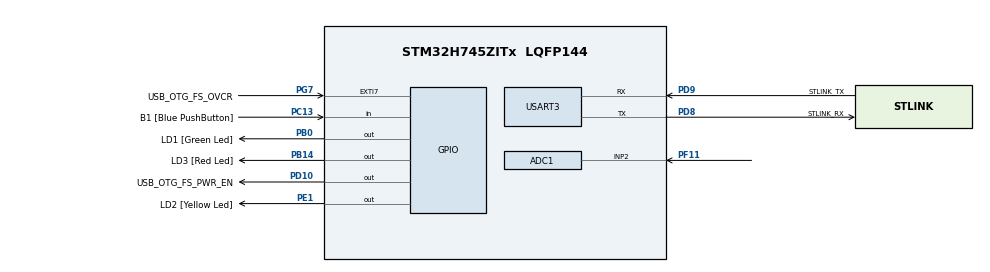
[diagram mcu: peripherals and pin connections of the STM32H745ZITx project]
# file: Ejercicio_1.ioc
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ADC1.Channel-0\#ChannelRegularConversion=ADC_CHANNEL_2
ADC1.ContinuousConvMode=ENABLE
ADC1.NbrOfConversionFlag=1
ADC1.OffsetNumber-0\#ChannelRegularConversion=ADC_OFFSET_NONE
ADC1.OffsetSignedSaturation-0\#ChannelRegularConversion=DISABLE
ADC1.Rank-0\#ChannelRegularConversion=1
ADC1.Resolution=ADC_RESOLUTION_8B
ADC1.SamplingTime-0\#ChannelRegularConversion=ADC_SAMPLETIME_1CYCLE_5
ADC1.master=1
CortexM4.IPs=FATFS_M4\:I,FREERTOS_M4\:I,IWDG2\:I,RCC,WWDG2\:I,DMA,BDMA,MDMA,NVIC2\:I,USART3,DEBUG,USB_DEVICE_M4\:I,USB_HOST_M4\:I,PDM2PCM_M4\:I,PWR,RESMGR_UTILITY,SYS_M4\:I,CORTEX_M4\:I,OPENAMP_M4\:I,VREFBUF,GPIO
CortexM7.IPs=FATFS_M7\:I,FREERTOS_M7\:I,IWDG1\:I,RCC\:I,WWDG1\:I,DMA\:I,BDMA\:I,MDMA\:I,NVIC1\:I,SYS\:I,USART3\:I,CORTEX_M7\:I,DEBUG\:I,USB_DEVICE_M7\:I,USB_HOST_M7\:I,PDM2PCM_M7\:I,PWR\:I,RESMGR_UTILITY\:I,OPENAMP_M7\:I,VREFBUF\:I,GPIO\:I,ADC1\:I
Mcu.Family=STM32H7
Mcu.Name=STM32H745ZITx
Mcu.Package=LQFP144
NVIC1.PriorityGroup=NVIC_PRIORITYGROUP_4
NVIC2.PriorityGroup=NVIC_PRIORITYGROUP_4
PA1.PinAttribute=CortexM7
PA1.Signal=ETH_REF_CLK
PA11.PinAttribute=CortexM7
PA11.Signal=USB_OTG_FS_DM
PA12.PinAttribute=CortexM7
PA12.Signal=USB_OTG_FS_DP
PA2.PinAttribute=CortexM7
PA2.Signal=ETH_MDIO
PA7.PinAttribute=CortexM7
PA7.Signal=ETH_CRS_DV
PA8.PinAttribute=CortexM7
PA8.Signal=USB_OTG_FS_SOF
PA9.PinAttribute=CortexM7
PA9.Signal=USB_OTG_FS_VBUS
PB0.GPIO_Label=LD1 [Green Led]
PB0.PinAttribute=Free
PB0.Signal=GPIO_Output
PB13.PinAttribute=CortexM7
PB13.Signal=ETH_TXD1
PB14.GPIO_Label=LD3 [Red Led]
PB14.PinAttribute=Free
PB14.Signal=GPIO_Output
PC1.PinAttribute=CortexM7
PC1.Signal=ETH_MDC
PC13.GPIO_Label=B1 [Blue PushButton]
PC13.PinAttribute=Free
PC13.Signal=GPIO_Input
PC14-OSC32_IN\ (OSC32_IN).Mode=LSE-External-Oscillator
PC14-OSC32_IN\ (OSC32_IN).PinAttribute=CortexM7
PC14-OSC32_IN\ (OSC32_IN).Signal=RCC_OSC32_IN
PC15-OSC32_OUT\ (OSC32_OUT).Mode=LSE-External-Oscillator
PC15-OSC32_OUT\ (OSC32_OUT).PinAttribute=CortexM7
PC15-OSC32_OUT\ (OSC32_OUT).Signal=RCC_OSC32_OUT
PC4.PinAttribute=CortexM7
PC4.Signal=ETH_RXD0
PC5.PinAttribute=CortexM7
PC5.Signal=ETH_RXD1
PD10.GPIO_Label=USB_OTG_FS_PWR_EN
PD10.PinAttribute=Free
PD10.Signal=GPIO_Output
PD8.GPIO_Label=STLINK_RX
PD8.Mode=Asynchronous
PD8.PinAttribute=CortexM7
PD8.Signal=USART3_TX
PD9.GPIO_Label=STLINK_TX
PD9.Mode=Asynchronous
PD9.PinAttribute=CortexM7
PD9.Signal=USART3_RX
PE1.GPIO_Label=LD2 [Yellow Led]
PE1.PinAttribute=Free
PE1.Signal=GPIO_Output
PF11.PinAttribute=CortexM7
PF11.Signal=SharedAnalog_PF11
PG11.PinAttribute=CortexM7
PG11.Signal=ETH_TX_EN
PG13.PinAttribute=CortexM7
PG13.Signal=ETH_TXD0
PG7.GPIO_Label=USB_OTG_FS_OVCR
PG7.PinAttribute=Free
PG7.Signal=GPXTI7
PH0-OSC_IN\ (PH0).Mode=HSE-External-Clock-Source
PH0-OSC_IN\ (PH0).PinAttribute=CortexM7
PH0-OSC_IN\ (PH0).Signal=RCC_OSC_IN
PH1-OSC_OUT\ (PH1).PinAttribute=CortexM7
PH1-OSC_OUT\ (PH1).Signal=RCC_OSC_OUT
ProjectManager.HeapSize=M4-0x200,M7-0x200
ProjectManager.StackSize=M4-0x400,M7-0x400
ProjectManager.TargetToolchain=STM32CubeIDE
RCC.ADCFreq_Value=76000000
RCC.APB1Freq_Value=120000000
RCC.APB2Freq_Value=120000000
RCC.APB3Freq_Value=120000000
RCC.APB4Freq_Value=120000000
RCC.CortexFreq_Value=480000000
RCC.D1PPRE=RCC_APB3_DIV2
RCC.D2PPRE1=RCC_APB1_DIV2
RCC.D2PPRE2=RCC_APB2_DIV2
RCC.D3PPRE=RCC_APB4_DIV2
RCC.DIVM1=1
RCC.DIVM2=1
RCC.DIVM3=1
RCC.DIVN1=120
RCC.DIVN2=19
RCC.DIVN3=24
RCC.DIVQ3=4
RCC.HCLKFreq_Value=240000000
RCC.HPRE=RCC_HCLK_DIV2
RCC.HSE_VALUE=8000000
RCC.PLL2FRACN=0
RCC.PLL3FRACN=0
RCC.PLLFRACN=0
RCC.PLLSourceVirtual=RCC_PLLSOURCE_HSE
RCC.SYSCLKFreq_VALUE=480000000
RCC.SYSCLKSource=RCC_SYSCLKSOURCE_PLLCLK
RCC.SupplySource=PWR_DIRECT_SMPS_SUPPLY
RCC.USBCLockSelection=RCC_USBCLKSOURCE_PLL3
RCC.USBFreq_Value=48000000
SH.SharedAnalog_PF11.0=GPIO_Analog
SH.SharedAnalog_PF11.1=ADC1_INP2,IN2-Single-Ended
USART3.VirtualMode-Asynchronous=VM_ASYNC
VP_SYS_M4_VS_Systick.Mode=SysTick
board=NUCLEO-H745ZI-Q

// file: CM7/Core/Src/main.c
/* USER CODE BEGIN Header */
/**
  ******************************************************************************
  * @file           : main.c
  * @brief          : Main program body
  ******************************************************************************
  * @attention
  *
  * Copyright (c) 2022 STMicroelectronics.
  * All rights reserved.
  *
  * This software is licensed under terms that can be found in the LICENSE file
  * in the root directory of this software component.
  * If no LICENSE file comes with this software, it is provided AS-IS.
  *
  ******************************************************************************
  */
/* USER CODE END Header */
#include "main.h"

/* USER CODE BEGIN PD */

#ifndef HSEM_ID_0
#define HSEM_ID_0 (0U) /* HW semaphore 0*/
#endif
/* USER CODE END PD */

ADC_HandleTypeDef hadc1;

UART_HandleTypeDef huart3;

/* USER CODE BEGIN PV */

// Variables UART
char uart_buf[50];
uint16_t uart_buf_len;

uint8_t adc_read;
/* USER CODE END PV */

void SystemClock_Config(void);
static void MX_GPIO_Init(void);
static void MX_USART3_UART_Init(void);
static void MX_ADC1_Init(void);
/* USER CODE BEGIN PFP */
static void printUART_int(char *string, int var);
/* USER CODE END PFP */

int main(void)
{
/* USER CODE BEGIN Boot_Mode_Sequence_0 */
  int32_t timeout;
/* USER CODE END Boot_Mode_Sequence_0 */

/* USER CODE BEGIN Boot_Mode_Sequence_1 */
  /* Wait until CPU2 boots and enters in stop mode or timeout*/
  timeout = 0xFFFF;
  while((__HAL_RCC_GET_FLAG(RCC_FLAG_D2CKRDY) != RESET) && (timeout-- > 0));
  if ( timeout < 0 )
  {
  Error_Handler();
  }
/* USER CODE END Boot_Mode_Sequence_1 */
  /* MCU Configuration--------------------------------------------------------*/

  /* Reset of all peripherals, Initializes the Flash interface and the Systick. */
  HAL_Init();

  /* Configure the system clock */
  SystemClock_Config();
/* USER CODE BEGIN Boot_Mode_Sequence_2 */
/* When system initialization is finished, Cortex-M7 will release Cortex-M4 by means of
HSEM notification */
/*HW semaphore Clock enable*/
__HAL_RCC_HSEM_CLK_ENABLE();
/*Take HSEM */
HAL_HSEM_FastTake(HSEM_ID_0);
/*Release HSEM in order to notify the CPU2(CM4)*/
HAL_HSEM_Release(HSEM_ID_0,0);
/* wait until CPU2 wakes up from stop mode */
timeout = 0xFFFF;
while((__HAL_RCC_GET_FLAG(RCC_FLAG_D2CKRDY) == RESET) && (timeout-- > 0));
if ( timeout < 0 )
{
Error_Handler();
}
/* USER CODE END Boot_Mode_Sequence_2 */

  /* Initialize all configured peripherals */
  MX_GPIO_Init();
  MX_USART3_UART_Init();
  MX_ADC1_Init();
  /* USER CODE BEGIN 2 */
  //HAL_ADCEx_Calibration_Start(&hadc1);
  /* USER CODE END 2 */

  /* Infinite loop */
  while (1)
  {

    /* USER CODE BEGIN 3 */
	  HAL_ADC_Start(&hadc1);
      HAL_ADC_PollForConversion(&hadc1, 10);
      adc_read = HAL_ADC_GetValue(&hadc1);
      HAL_ADC_Stop(&hadc1);

      printUART_int("Valor ADC: %u \r\n", adc_read);

  }
  /* USER CODE END 3 */
}

void SystemClock_Config(void)
{
  RCC_OscInitTypeDef RCC_OscInitStruct = {0};
  RCC_ClkInitTypeDef RCC_ClkInitStruct = {0};

  /** Supply configuration update enable
  */
  HAL_PWREx_ConfigSupply(PWR_DIRECT_SMPS_SUPPLY);

  /** Configure the main internal regulator output voltage
  */
  __HAL_PWR_VOLTAGESCALING_CONFIG(PWR_REGULATOR_VOLTAGE_SCALE0);

  while(!__HAL_PWR_GET_FLAG(PWR_FLAG_VOSRDY)) {}

  /** Macro to configure the PLL clock source
  */
  __HAL_RCC_PLL_PLLSOURCE_CONFIG(RCC_PLLSOURCE_HSE);

  /** Initializes the RCC Oscillators according to the specified parameters
  * in the RCC_OscInitTypeDef structure.
  */
  RCC_OscInitStruct.OscillatorType = RCC_OSCILLATORTYPE_HSE;
  RCC_OscInitStruct.HSEState = RCC_HSE_BYPASS;
  RCC_OscInitStruct.PLL.PLLState = RCC_PLL_ON;
  RCC_OscInitStruct.PLL.PLLSource = RCC_PLLSOURCE_HSE;
  RCC_OscInitStruct.PLL.PLLM = 1;
  RCC_OscInitStruct.PLL.PLLN = 120;
  RCC_OscInitStruct.PLL.PLLP = 2;
  RCC_OscInitStruct.PLL.PLLQ = 2;
  RCC_OscInitStruct.PLL.PLLR = 2;
  RCC_OscInitStruct.PLL.PLLRGE = RCC_PLL1VCIRANGE_3;
  RCC_OscInitStruct.PLL.PLLVCOSEL = RCC_PLL1VCOWIDE;
  RCC_OscInitStruct.PLL.PLLFRACN = 0;
  if (HAL_RCC_OscConfig(&RCC_OscInitStruct) != HAL_OK)
  {
    Error_Handler();
  }

  /** Initializes the CPU, AHB and APB buses clocks
  */
  RCC_ClkInitStruct.ClockType = RCC_CLOCKTYPE_HCLK|RCC_CLOCKTYPE_SYSCLK
                              |RCC_CLOCKTYPE_PCLK1|RCC_CLOCKTYPE_PCLK2
                              |RCC_CLOCKTYPE_D3PCLK1|RCC_CLOCKTYPE_D1PCLK1;
  RCC_ClkInitStruct.SYSCLKSource = RCC_SYSCLKSOURCE_PLLCLK;
  RCC_ClkInitStruct.SYSCLKDivider = RCC_SYSCLK_DIV1;
  RCC_ClkInitStruct.AHBCLKDivider = RCC_HCLK_DIV2;
  RCC_ClkInitStruct.APB3CLKDivider = RCC_APB3_DIV2;
  RCC_ClkInitStruct.APB1CLKDivider = RCC_APB1_DIV2;
  RCC_ClkInitStruct.APB2CLKDivider = RCC_APB2_DIV2;
  RCC_ClkInitStruct.APB4CLKDivider = RCC_APB4_DIV2;

  if (HAL_RCC_ClockConfig(&RCC_ClkInitStruct, FLASH_LATENCY_4) != HAL_OK)
  {
    Error_Handler();
  }
}

static void MX_ADC1_Init(void)
{

  ADC_MultiModeTypeDef multimode = {0};
  ADC_ChannelConfTypeDef sConfig = {0};

  /** Common config
  */
  hadc1.Instance = ADC1;
  hadc1.Init.ClockPrescaler = ADC_CLOCK_ASYNC_DIV1;
  hadc1.Init.Resolution = ADC_RESOLUTION_8B;
  hadc1.Init.ScanConvMode = ADC_SCAN_DISABLE;
  hadc1.Init.EOCSelection = ADC_EOC_SINGLE_CONV;
  hadc1.Init.LowPowerAutoWait = DISABLE;
  hadc1.Init.ContinuousConvMode = ENABLE;
  hadc1.Init.NbrOfConversion = 1;
  hadc1.Init.DiscontinuousConvMode = DISABLE;
  hadc1.Init.ExternalTrigConv = ADC_SOFTWARE_START;
  hadc1.Init.ExternalTrigConvEdge = ADC_EXTERNALTRIGCONVEDGE_NONE;
  hadc1.Init.ConversionDataManagement = ADC_CONVERSIONDATA_DR;
  hadc1.Init.Overrun = ADC_OVR_DATA_PRESERVED;
  hadc1.Init.LeftBitShift = ADC_LEFTBITSHIFT_NONE;
  hadc1.Init.OversamplingMode = DISABLE;
  if (HAL_ADC_Init(&hadc1) != HAL_OK)
  {
    Error_Handler();
  }

  /** Configure the ADC multi-mode
  */
  multimode.Mode = ADC_MODE_INDEPENDENT;
  if (HAL_ADCEx_MultiModeConfigChannel(&hadc1, &multimode) != HAL_OK)
  {
    Error_Handler();
  }

  /** Configure Regular Channel
  */
  sConfig.Channel = ADC_CHANNEL_2;
  sConfig.Rank = ADC_REGULAR_RANK_1;
  sConfig.SamplingTime = ADC_SAMPLETIME_1CYCLE_5;
  sConfig.SingleDiff = ADC_SINGLE_ENDED;
  sConfig.OffsetNumber = ADC_OFFSET_NONE;
  sConfig.Offset = 0;
  sConfig.OffsetSignedSaturation = DISABLE;
  if (HAL_ADC_ConfigChannel(&hadc1, &sConfig) != HAL_OK)
  {
    Error_Handler();
  }

}

static void MX_USART3_UART_Init(void)
{

  huart3.Instance = USART3;
  huart3.Init.BaudRate = 115200;
  huart3.Init.WordLength = UART_WORDLENGTH_8B;
  huart3.Init.StopBits = UART_STOPBITS_1;
  huart3.Init.Parity = UART_PARITY_NONE;
  huart3.Init.Mode = UART_MODE_TX_RX;
  huart3.Init.HwFlowCtl = UART_HWCONTROL_NONE;
  huart3.Init.OverSampling = UART_OVERSAMPLING_16;
  huart3.Init.OneBitSampling = UART_ONE_BIT_SAMPLE_DISABLE;
  huart3.Init.ClockPrescaler = UART_PRESCALER_DIV1;
  huart3.AdvancedInit.AdvFeatureInit = UART_ADVFEATURE_NO_INIT;
  if (HAL_UART_Init(&huart3) != HAL_OK)
  {
    Error_Handler();
  }
  if (HAL_UARTEx_SetTxFifoThreshold(&huart3, UART_TXFIFO_THRESHOLD_1_8) != HAL_OK)
  {
    Error_Handler();
  }
  if (HAL_UARTEx_SetRxFifoThreshold(&huart3, UART_RXFIFO_THRESHOLD_1_8) != HAL_OK)
  {
    Error_Handler();
  }
  if (HAL_UARTEx_DisableFifoMode(&huart3) != HAL_OK)
  {
    Error_Handler();
  }

}

static void MX_GPIO_Init(void)
{

  /* GPIO Ports Clock Enable */
  __HAL_RCC_GPIOC_CLK_ENABLE();
  __HAL_RCC_GPIOH_CLK_ENABLE();
  __HAL_RCC_GPIOF_CLK_ENABLE();
  __HAL_RCC_GPIOD_CLK_ENABLE();

}

/* USER CODE BEGIN 4 */
static void printUART_int(char *string, int var){
	uart_buf_len = sprintf(uart_buf, string, var);
	HAL_UART_Transmit(&huart3, (uint8_t *)uart_buf, uart_buf_len, 100);
}
/* USER CODE END 4 */

void Error_Handler(void)
{
  __disable_irq();
  while (1)
  {
  }
}
